# STM32F102RBT6 register map
File version: 1.0
Registers are 32-bit, access not given, reset 0x0 unless marked. A register's access mark holds for its fields unless they carry their own. Offsets are from the block's base; [hi:lo] are bit positions; {n}, {i} and the like mark numbered series; 'fields as' and 'values as' point back to an identical list.

## I2C1
Base 0x40005400
Same registers: I2C2 0x40005800
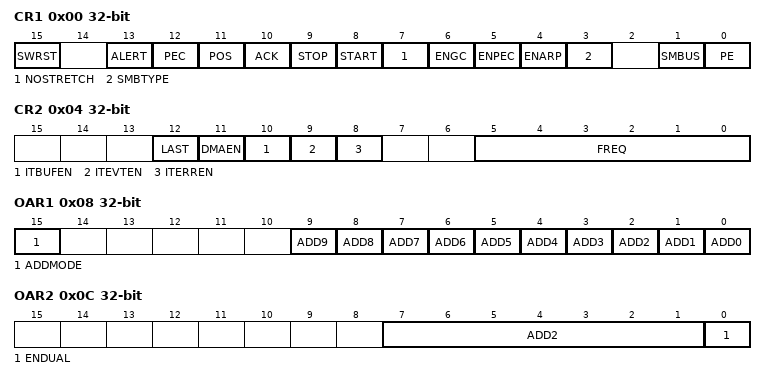
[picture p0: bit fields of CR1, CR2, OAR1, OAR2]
0x00 CR1
  [15] SWRST, [13] ALERT, [12] PEC, [11] POS, [10] ACK, [9] STOP, [8] START, [7] NOSTRETCH, [6] ENGC, [5] ENPEC, [4] ENARP, [3] SMBTYPE, [1] SMBUS, [0] PE
0x04 CR2
  [12] LAST, [11] DMAEN, [10] ITBUFEN, [9] ITEVTEN, [8] ITERREN, [5:0] FREQ
0x08 OAR1
  [15] ADDMODE, [n] ADD{n} (n=0..9)
0x0C OAR2
  [7:1] ADD2, [0] ENDUAL
0x10 DR
  [7:0] DR
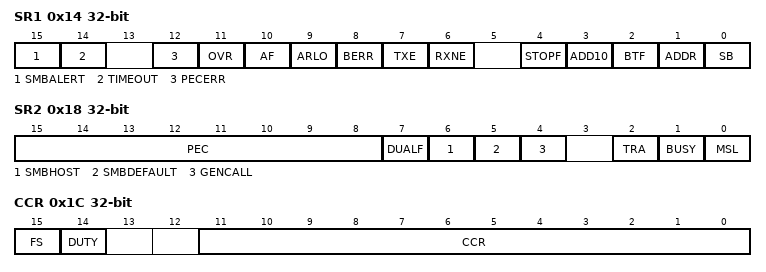
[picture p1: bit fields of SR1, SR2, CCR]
0x14 SR1
  [15] SMBALERT, [14] TIMEOUT, [12] PECERR, [11] OVR, [10] AF, [9] ARLO, [8] BERR, [7] TXE, [6] RXNE, [4] STOPF, [3] ADD10, [2] BTF, [1] ADDR, [0] SB
0x18 SR2
  [15:8] PEC, [7] DUALF, [6] SMBHOST, [5] SMBDEFAULT, [4] GENCALL, [2] TRA, [1] BUSY, [0] MSL
0x1C CCR
  [15] FS, [14] DUTY, [11:0] CCR
0x20 TRISE
  [5:0] TRISE

## USB
Base 0x40005C00
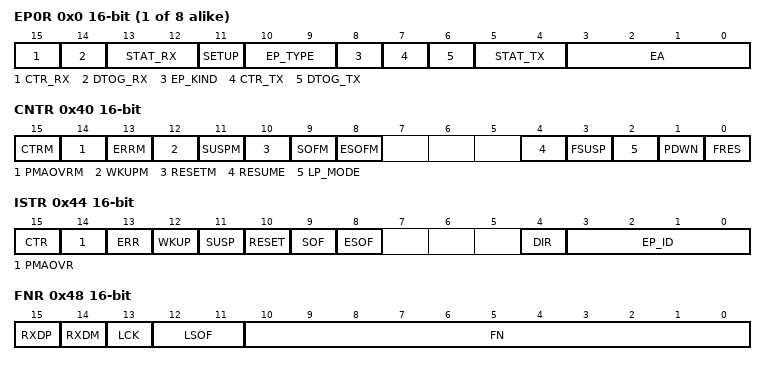
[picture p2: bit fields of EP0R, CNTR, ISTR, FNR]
{0x0+4i} EP{i}R 16-bit (i=0..7)
  [15] CTR_RX, [14] DTOG_RX, [13:12] STAT_RX, [11] SETUP, [10:9] EP_TYPE, [8] EP_KIND, [7] CTR_TX, [6] DTOG_TX, [5:4] STAT_TX, [3:0] EA
0x40 CNTR 16-bit
  [15] CTRM, [14] PMAOVRM, [13] ERRM, [12] WKUPM, [11] SUSPM, [10] RESETM, [9] SOFM, [8] ESOFM, [4] RESUME, [3] FSUSP, [2] LP_MODE, [1] PDWN, [0] FRES
0x44 ISTR 16-bit
  [15] CTR, [14] PMAOVR, [13] ERR, [12] WKUP, [11] SUSP, [10] RESET, [9] SOF, [8] ESOF, [4] DIR, [3:0] EP_ID
0x48 FNR 16-bit
  [15] RXDP, [14] RXDM, [13] LCK, [12:11] LSOF, [10:0] FN
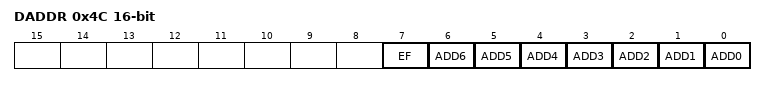
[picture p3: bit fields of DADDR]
0x4C DADDR 16-bit
  [7] EF, [n] ADD{n} (n=0..6)
0x50 BTABLE 16-bit
  [15:3] BTABLE

## BKP
Base 0x40006C00
{0x0+4i} DR{i} (i=1..10)
  [15:0] D
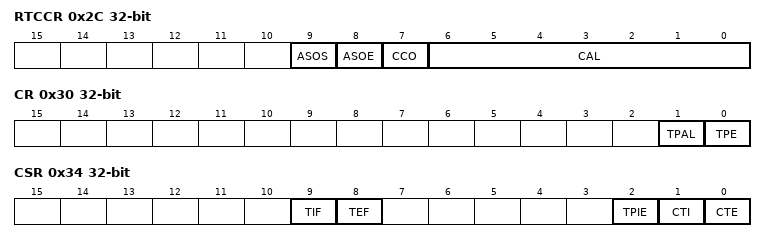
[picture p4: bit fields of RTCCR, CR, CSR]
0x2C RTCCR
  [9] ASOS, [8] ASOE, [7] CCO, [6:0] CAL
0x30 CR
  [1] TPAL, [0] TPE
0x34 CSR
  [9] TIF, [8] TEF, [2] TPIE, [1] CTI, [0] CTE

## PWR
Base 0x40007000
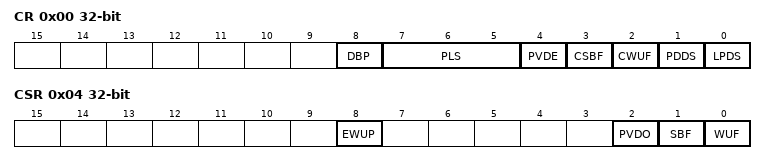
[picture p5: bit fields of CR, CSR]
0x00 CR
  [8] DBP, [7:5] PLS, [4] PVDE, [3] CSBF, [2] CWUF, [1] PDDS, [0] LPDS
0x04 CSR
  [8] EWUP, [2] PVDO, [1] SBF, [0] WUF

## AFIO
Base 0x40010000
0x00 EVCR
  [7] EVOE, [6] PORT_PE, [5] PORT_PC, [5:4] PORT_PD, [3] PIN_PX8, [2] PIN_PX4, [2:1] PIN_PX6, [3:0] PIN_PX9
0x04 MAPR
  [26] SWJ_CFG_DISABLE, [25] SWJ_CFG_JTAGDISABLE, [24] SWJ_CFG_NOJNTRST, [15] PD01_REMAP, [12] TIM4_REMAP, [11] TIM3_REMAP_PARTIALREMAP, [11:10] TIM3_REMAP_FULLREMAP, [9] TIM2_REMAP_PARTIALREMAP2, [8] TIM2_REMAP_PARTIALREMAP1, [6] TIM1_REMAP_PARTIALREMAP, [4] USART3_REMAP_PARTIALREMAP, [3] USART2_REMAP, [2] USART1_REMAP, [1] I2C1_REMAP, [0] SPI1_REMAP
0x08 EXTICR.0
  [4n+2] EXTI{n}_PE (n=0..3), [4n+2:4n+1] EXTI{n}_PG (n=0..3), [4n+2:4n] EXTI{n}_PF (n=0..3)
0x0C EXTICR.1
  [4n-14] EXTI{n}_PE (n=4..7), [4n-14:4n-15] EXTI{n}_PG (n=4..7), [4n-14:4n-16] EXTI{n}_PF (n=4..7)
0x10 EXTICR.2
  [4n-30] EXTI{n}_PE (n=8..11), [4n-30:4n-31] EXTI{n}_PG (n=8..11), [4n-30:4n-32] EXTI{n}_PF (n=8..11)
0x14 EXTICR.3
  [4n-46] EXTI{n}_PE (n=12..15), [4n-46:4n-47] EXTI{n}_PG (n=12..15), [4n-46:4n-48] EXTI{n}_PF (n=12..15)
0x1C MAPR2

## EXTI
Base 0x40010400
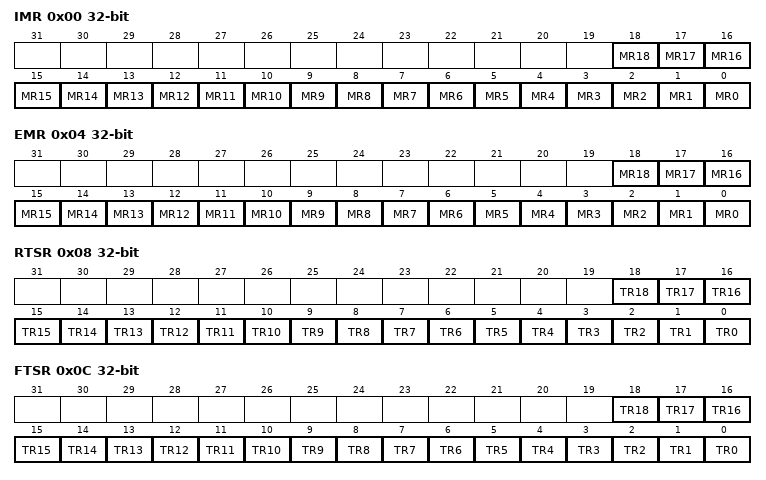
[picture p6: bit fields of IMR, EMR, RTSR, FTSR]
0x00 IMR
  [n] MR{n} (n=0..18)
0x04 EMR
  [n] MR{n} (n=0..18)
0x08 RTSR
  [n] TR{n} (n=0..18)
0x0C FTSR
  [n] TR{n} (n=0..18)
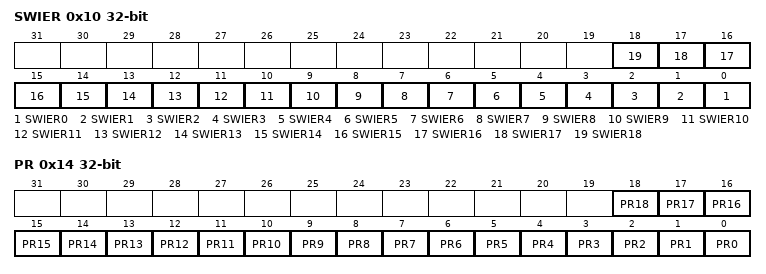
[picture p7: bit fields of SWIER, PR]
0x10 SWIER
  [n] SWIER{n} (n=0..18)
0x14 PR
  [n] PR{n} (n=0..18)

## GPIOA
Base 0x40010800
Same registers: GPIOB 0x40010C00, GPIOC 0x40011000, GPIOD 0x40011400
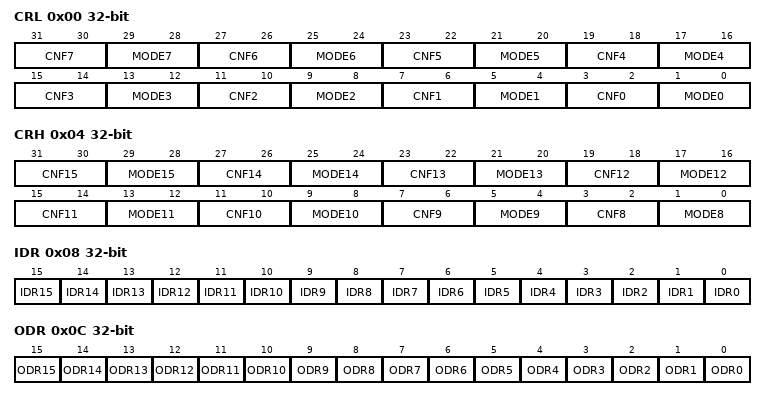
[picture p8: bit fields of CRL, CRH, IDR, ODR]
0x00 CRL
  [4n+3:4n+2] CNF{n} (n=0..7), [4n+1:4n] MODE{n} (n=0..7)
0x04 CRH
  [4n-29:4n-30] CNF{n} (n=8..15), [4n-31:4n-32] MODE{n} (n=8..15)
0x08 IDR
  [n] IDR{n} (n=0..15)
0x0C ODR
  [n] ODR{n} (n=0..15)
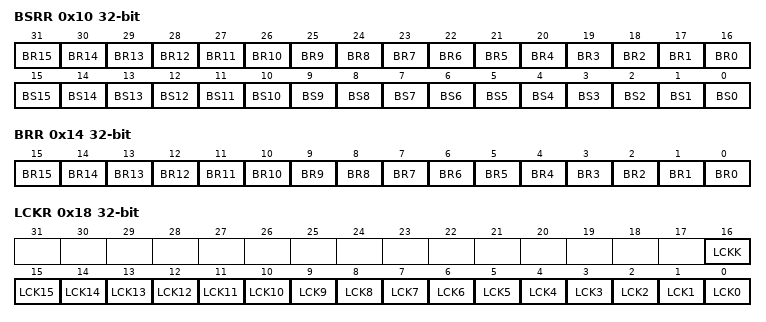
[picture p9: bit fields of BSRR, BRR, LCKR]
0x10 BSRR
  [n+16] BR{n} (n=0..15), [n] BS{n} (n=0..15)
0x14 BRR
  [n] BR{n} (n=0..15)
0x18 LCKR
  [16] LCKK, [n] LCK{n} (n=0..15)

## ADC1
Base 0x40012400
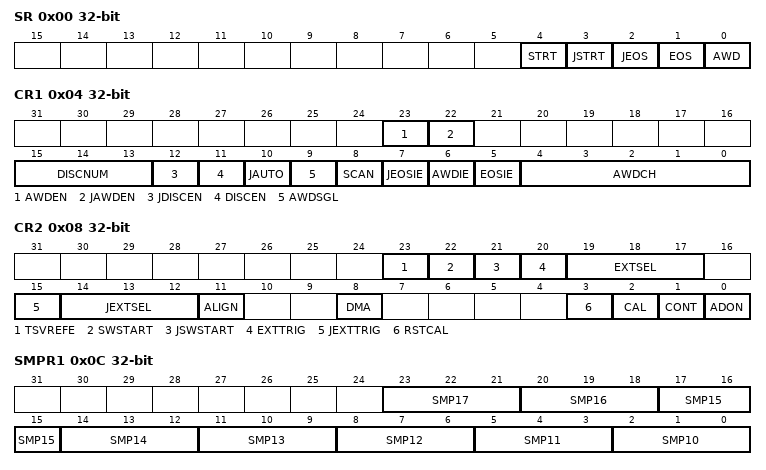
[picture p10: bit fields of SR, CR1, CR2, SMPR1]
0x00 SR
  [4] STRT, [3] JSTRT, [2] JEOS, [1] EOS, [0] AWD
0x04 CR1
  [23] AWDEN, [22] JAWDEN, [15:13] DISCNUM, [12] JDISCEN, [11] DISCEN, [10] JAUTO, [9] AWDSGL, [8] SCAN, [7] JEOSIE, [6] AWDIE, [5] EOSIE, [4:0] AWDCH
0x08 CR2
  [23] TSVREFE, [22] SWSTART, [21] JSWSTART, [20] EXTTRIG, [19:17] EXTSEL, [15] JEXTTRIG, [14:12] JEXTSEL, [11] ALIGN, [8] DMA, [3] RSTCAL, [2] CAL, [1] CONT, [0] ADON
0x0C SMPR1
  [3n-28:3n-30] SMP{n} (n=10..17)
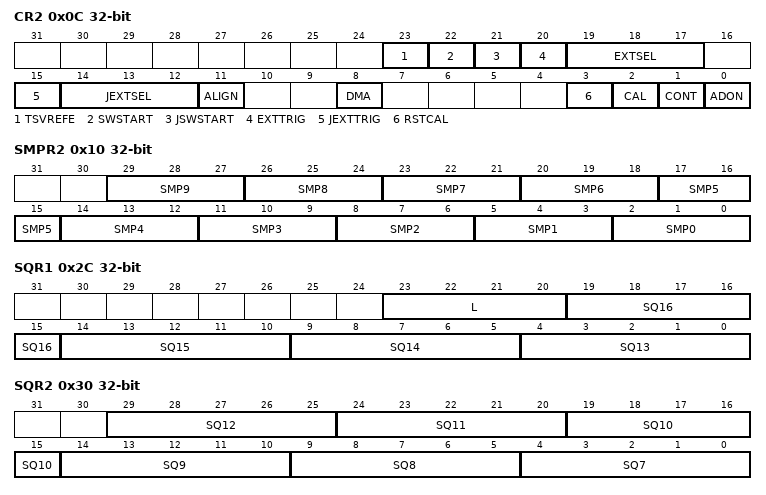
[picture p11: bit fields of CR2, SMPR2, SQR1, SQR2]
0x0C CR2
  fields as CR2
0x10 SMPR2
  [3n+2:3n] SMP{n} (n=0..9)
{0x10+4i} JOFR{i} (i=1..4)
  [11:0] JOFFSET{i}
0x24 HTR
  [11:0] HT
0x28 LTR
  [11:0] LT
0x2C SQR1
  [23:20] L, [5n-61:5n-65] SQ{n} (n=13..16)
0x30 SQR2
  [5n-31:5n-35] SQ{n} (n=7..12)
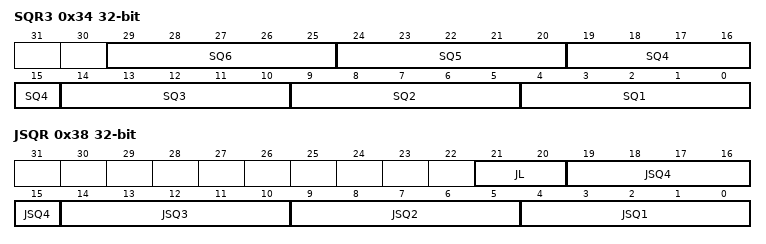
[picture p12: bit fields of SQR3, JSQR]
0x34 SQR3
  [5n-1:5n-5] SQ{n} (n=1..6)
0x38 JSQR
  [21:20] JL, [5n-1:5n-5] JSQ{n} (n=1..4)
{0x38+4i} JDR{i} (i=1..4)
  [15:0] JDATA
0x4C DR
  [15:0] DATA
0x58 DR
  [15:0] DATA

## DMA1
Base 0x40020000
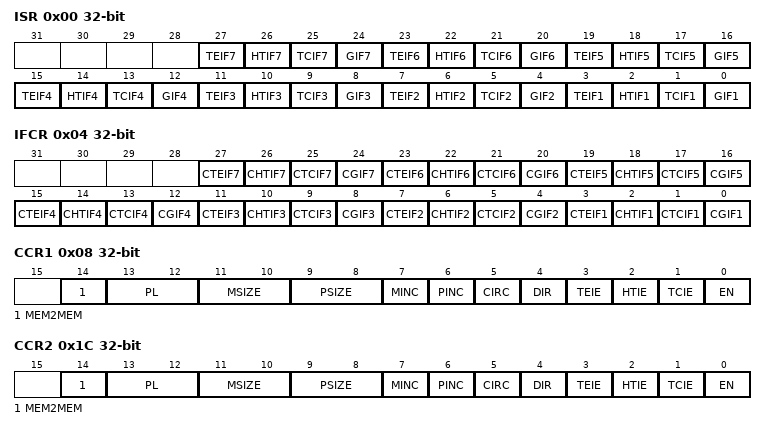
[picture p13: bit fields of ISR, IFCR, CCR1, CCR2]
0x00 ISR
  [4n-1] TEIF{n} (n=1..7), [4n-2] HTIF{n} (n=1..7), [4n-3] TCIF{n} (n=1..7), [4n-4] GIF{n} (n=1..7)
0x04 IFCR
  [4n-1] CTEIF{n} (n=1..7), [4n-2] CHTIF{n} (n=1..7), [4n-3] CTCIF{n} (n=1..7), [4n-4] CGIF{n} (n=1..7)
0x08 CCR1
  [14] MEM2MEM, [13:12] PL, [11:10] MSIZE, [9:8] PSIZE, [7] MINC, [6] PINC, [5] CIRC, [4] DIR, [3] TEIE, [2] HTIE, [1] TCIE, [0] EN
0x0C CNDTR1
  [15:0] NDT
0x10 CPAR1
  [31:0] PA
{0x0+0x14*i} CMAR{i} (i=1..7)
  [31:0] MA
0x1C CCR2
  fields as CCR1
0x20 CNDTR2
  [15:0] NDT
0x24 CPAR2
  [31:0] PA
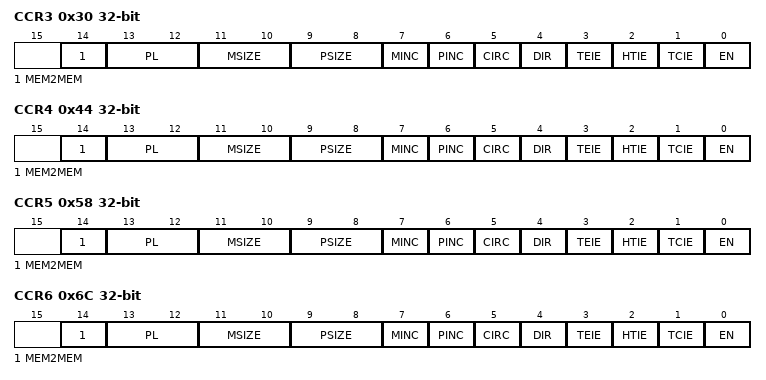
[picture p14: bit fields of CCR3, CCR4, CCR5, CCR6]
0x30 CCR3
  fields as CCR1
0x34 CNDTR3
  [15:0] NDT
0x38 CPAR3
  [31:0] PA
0x44 CCR4
  fields as CCR1
0x48 CNDTR4
  [15:0] NDT
0x4C CPAR4
  [31:0] PA
0x58 CCR5
  fields as CCR1
0x5C CNDTR5
  [15:0] NDT
0x60 CPAR5
  [31:0] PA
0x6C CCR6
  fields as CCR1
0x70 CNDTR6
  [15:0] NDT
0x74 CPAR6
  [31:0] PA
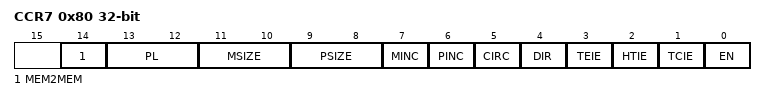
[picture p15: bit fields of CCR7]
0x80 CCR7
  fields as CCR1
0x84 CNDTR7
  [15:0] NDT
0x88 CPAR7
  [31:0] PA

## RCC
Base 0x40021000
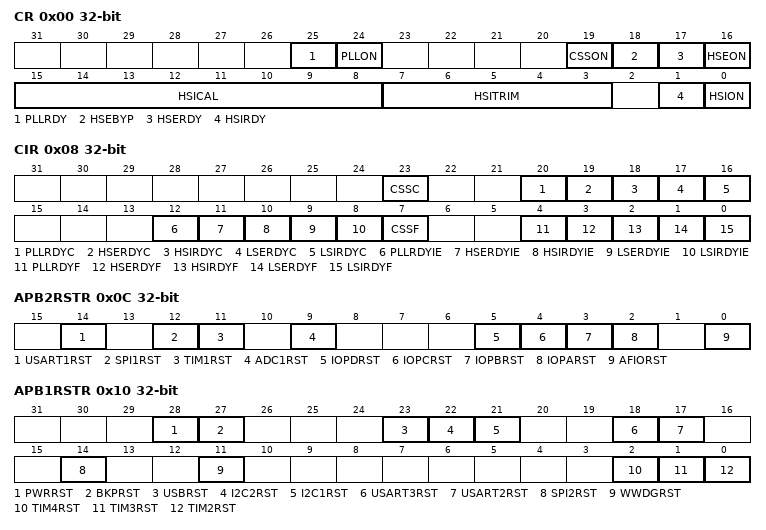
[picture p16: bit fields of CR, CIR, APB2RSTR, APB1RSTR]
0x00 CR
  [25] PLLRDY, [24] PLLON, [19] CSSON, [18] HSEBYP, [17] HSERDY, [16] HSEON, [15:8] HSICAL, [7:3] HSITRIM, [1] HSIRDY, [0] HSION
0x04 CFGR
  [26:24] MCO, [22] USBPRE, [21] PLLMULL10, [20] PLLMULL6, [20:19] PLLMULL8, [20:18] PLLMULL9, [17] PLLXTPRE, [16] PLLSRC, [15:14] ADCPRE, [13:11] PPRE2, [10:8] PPRE1, [7:4] HPRE, [3:2] SWS, [1:0] SW
0x08 CIR
  [23] CSSC, [20] PLLRDYC, [19] HSERDYC, [18] HSIRDYC, [17] LSERDYC, [16] LSIRDYC, [12] PLLRDYIE, [11] HSERDYIE, [10] HSIRDYIE, [9] LSERDYIE, [8] LSIRDYIE, [7] CSSF, [4] PLLRDYF, [3] HSERDYF, [2] HSIRDYF, [1] LSERDYF, [0] LSIRDYF
0x0C APB2RSTR
  [14] USART1RST, [12] SPI1RST, [11] TIM1RST, [9] ADC1RST, [5] IOPDRST, [4] IOPCRST, [3] IOPBRST, [2] IOPARST, [0] AFIORST
0x10 APB1RSTR
  [28] PWRRST, [27] BKPRST, [23] USBRST, [22] I2C2RST, [21] I2C1RST, [18] USART3RST, [17] USART2RST, [14] SPI2RST, [11] WWDGRST, [2] TIM4RST, [1] TIM3RST, [0] TIM2RST
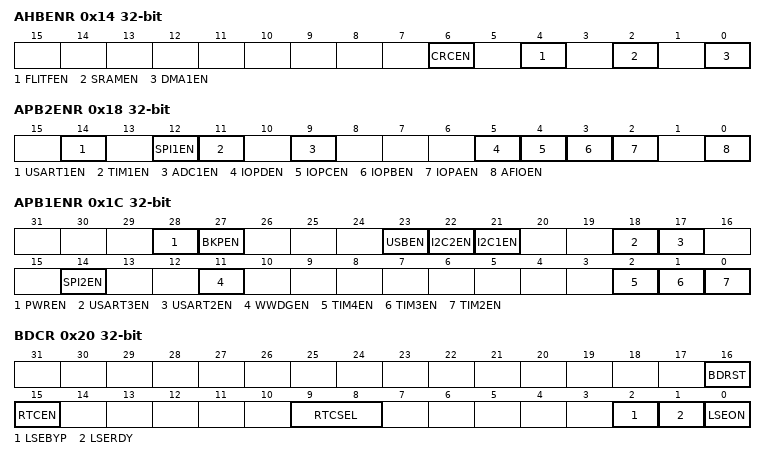
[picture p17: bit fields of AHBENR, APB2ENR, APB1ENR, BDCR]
0x14 AHBENR
  [6] CRCEN, [4] FLITFEN, [2] SRAMEN, [0] DMA1EN
0x18 APB2ENR
  [14] USART1EN, [12] SPI1EN, [11] TIM1EN, [9] ADC1EN, [5] IOPDEN, [4] IOPCEN, [3] IOPBEN, [2] IOPAEN, [0] AFIOEN
0x1C APB1ENR
  [28] PWREN, [27] BKPEN, [23] USBEN, [22] I2C2EN, [21] I2C1EN, [18] USART3EN, [17] USART2EN, [14] SPI2EN, [11] WWDGEN, [2] TIM4EN, [1] TIM3EN, [0] TIM2EN
0x20 BDCR
  [16] BDRST, [15] RTCEN, [9:8] RTCSEL, [2] LSEBYP, [1] LSERDY, [0] LSEON
0x24 CSR
  [31] LPWRRSTF, [30] WWDGRSTF, [29] IWDGRSTF, [28] SFTRSTF, [27] PORRSTF, [26] PINRSTF, [24] RMVF, [1] LSIRDY, [0] LSION

## FLASH
Base 0x40022000
0x00 ACR
  [5] PRFTBS, [4] PRFTBE, [3] HLFCYA, [2:0] LATENCY
0x04 KEYR
  [31:0] FKEYR
0x08 OPTKEYR
0x0C SR
  [5] EOP, [4] WRPRTERR, [2] PGERR, [0] BSY
0x10 CR
  [12] EOPIE, [10] ERRIE, [9] OPTWRE, [7] LOCK, [6] STRT, [5] OPTER, [4] OPTPG, [2] MER, [1] PER, [0] PG
0x14 AR
  [31:0] FAR
0x1C OBR
  [25:18] DATA1, [17:10] DATA0, [4] nRST_STDBY, [3] nRST_STOP, [4:2] USER, [1] RDPRT, [0] OPTERR
0x20 WRPR
  [31:0] WRP

## CRC
Base 0x40023000
0x00 DR
0x04 IDR 8-bit
0x08 CR
  [0] RESET

## DBGMCU
Base 0xE0042000
0x00 IDCODE
  [31:16] REV_ID, [11:0] DEV_ID
0x04 CR
  [16] DBG_I2C2_SMBUS_TIMEOUT, [15] DBG_I2C1_SMBUS_TIMEOUT, [13] DBG_TIM4_STOP, [12] DBG_TIM3_STOP, [11] DBG_TIM2_STOP, [9] DBG_WWDG_STOP, [8] DBG_IWDG_STOP, [7:6] TRACE_MODE, [5] TRACE_IOEN, [2] DBG_STANDBY, [1] DBG_STOP, [0] DBG_SLEEP
